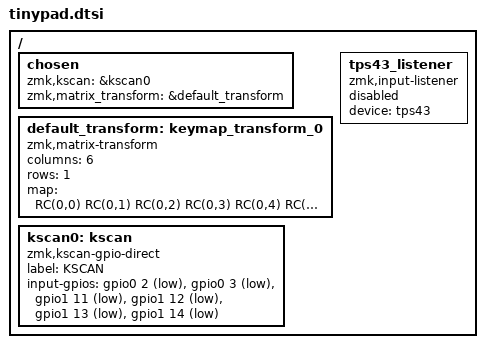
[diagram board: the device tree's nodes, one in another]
#include <input/processors.dtsi>
#include <dt-bindings/zmk/input_transform.h>
#include <dt-bindings/zmk/matrix_transform.h>

/ {
	chosen {
        zmk,kscan = &kscan0;
        zmk,matrix_transform = &default_transform;
	};

default_transform: keymap_transform_0 {
    compatible = "zmk,matrix-transform";
    columns = <6>;
    rows = <1>;
    map = <
        RC(0,0) RC(0,1) RC(0,2)  RC(0,3) RC(0,4) RC(0,5)
    >;
};

    kscan0: kscan {
        compatible = "zmk,kscan-gpio-direct";
        label = "KSCAN";
        input-gpios =
            <&gpio0 2 (GPIO_ACTIVE_LOW | GPIO_PULL_UP)>,
            <&gpio0 3 (GPIO_ACTIVE_LOW | GPIO_PULL_UP)>,
            <&gpio1 11 (GPIO_ACTIVE_LOW | GPIO_PULL_UP)>,
            <&gpio1 12 (GPIO_ACTIVE_LOW | GPIO_PULL_UP)>,
            <&gpio1 13 (GPIO_ACTIVE_LOW | GPIO_PULL_UP)>,
            <&gpio1 14 (GPIO_ACTIVE_LOW | GPIO_PULL_UP)>;
    };

	tps43_listener: tps43_listener {
        compatible = "zmk,input-listener";
        status = "disabled";
        device = <&tps43>;
    };


};
